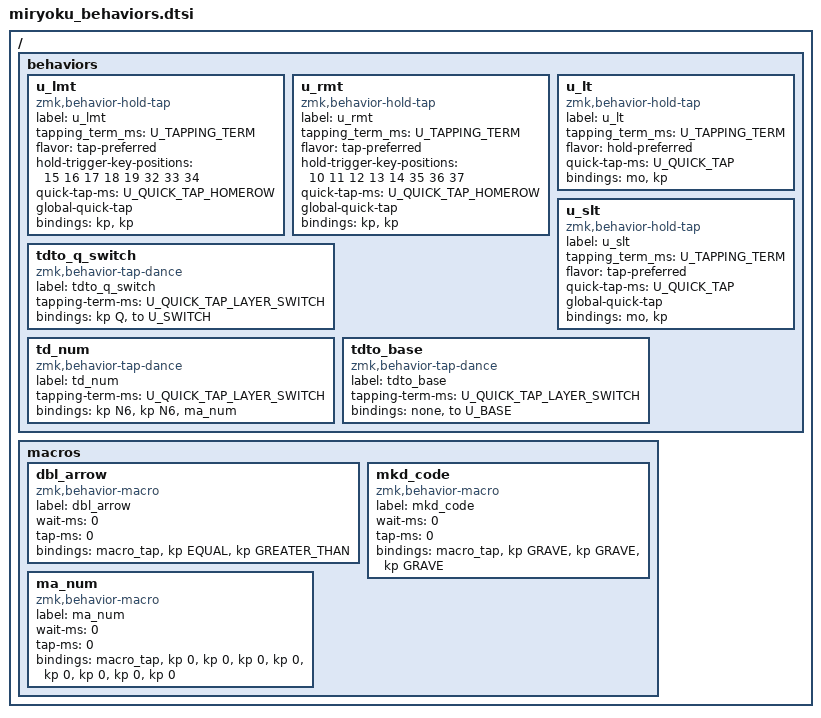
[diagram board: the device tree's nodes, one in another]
// Copyright 2022 Manna Harbour
// https://github.com/manna-harbour/miryoku

/ {
  behaviors {
    u_lmt: u_lmt {
      compatible = "zmk,behavior-hold-tap";
      label = "u_lmt";
      #binding-cells = <2>;
      tapping_term_ms = <U_TAPPING_TERM>;
      flavor = "tap-preferred";
      hold-trigger-key-positions = <15 16 17 18 19 32 33 34>;
      quick-tap-ms = <U_QUICK_TAP_HOMEROW>;
      global-quick-tap;
      bindings = <&kp>, <&kp>;
    };
    u_rmt: u_rmt {
      compatible = "zmk,behavior-hold-tap";
      label = "u_rmt";
      #binding-cells = <2>;
      tapping_term_ms = <U_TAPPING_TERM>;
      flavor = "tap-preferred";
      hold-trigger-key-positions = <10 11 12 13 14 35 36 37>;
      quick-tap-ms = <U_QUICK_TAP_HOMEROW>;
      global-quick-tap;
      bindings = <&kp>, <&kp>;
    };
    u_lt: u_lt {
      compatible = "zmk,behavior-hold-tap";
      label = "u_lt";
      #binding-cells = <2>;
      tapping_term_ms = <U_TAPPING_TERM>;
      flavor = "hold-preferred";
      quick-tap-ms = <U_QUICK_TAP>;
      bindings = <&mo>, <&kp>;
    };
    u_slt: u_slt {
      compatible = "zmk,behavior-hold-tap";
      label = "u_slt";
      #binding-cells = <2>;
      tapping_term_ms = <U_TAPPING_TERM>;
      flavor = "tap-preferred";
      quick-tap-ms = <U_QUICK_TAP>;
      global-quick-tap;
      bindings = <&mo>, <&kp>;
    };
    tdto_q_switch: tdto_q_switch {
      compatible = "zmk,behavior-tap-dance";
      label = "tdto_q_switch";
      #binding-cells = <0>;
      tapping-term-ms = <U_QUICK_TAP_LAYER_SWITCH>;
      bindings = <&kp Q>, <&to U_SWITCH>;
    };        
    td_num: td_num {
      compatible = "zmk,behavior-tap-dance";
      label = "td_num";
      #binding-cells = <0>;
      tapping-term-ms = <U_QUICK_TAP_LAYER_SWITCH>;
      bindings = <&kp N6>, <&kp N6>, <&ma_num>;
    };        
    tdto_base: tdto_base {
      compatible = "zmk,behavior-tap-dance";
      label = "tdto_base";
      #binding-cells = <0>;
      tapping-term-ms = <U_QUICK_TAP_LAYER_SWITCH>;
      bindings = <&none>, <&to U_BASE>;
    };
  };
};

/ {
    macros {
        dbl_arrow: dbl_arrow {
            label = "dbl_arrow";
            compatible = "zmk,behavior-macro";
            wait-ms = <0>;
            tap-ms = <0>;
            #binding-cells = <0>;
            bindings = <&macro_tap &kp EQUAL &kp GREATER_THAN>;
        };
        mkd_code: mkd_code {
            label = "mkd_code";
            compatible = "zmk,behavior-macro";
            wait-ms = <0>;
            tap-ms = <0>;
            #binding-cells = <0>;
            bindings = <&macro_tap &kp GRAVE &kp GRAVE &kp GRAVE>;
        };
        ma_num: ma_num {
            label = "ma_num";
            compatible = "zmk,behavior-macro";
            wait-ms = <0>;
            tap-ms = <0>;
            #binding-cells = <0>;
            bindings = <&macro_tap &kp 0 &kp 0 &kp 0 &kp 0 &kp 0 &kp 0 &kp 0 &kp 0>;
        };
    };
};
